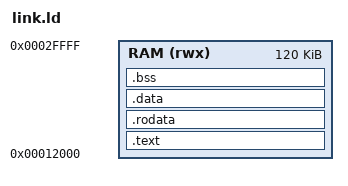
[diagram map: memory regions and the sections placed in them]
MEMORY {
	RAM (rwx): ORIGIN = 0x10000+0x2000, LENGTH = 128k-0x2000
}

ENTRY(_start);

SECTIONS {
	.text : {
		*(.text.startup)
		*(.text)
		*(.text.*)
	} >RAM

	.rodata : {
		*(.rodata)
		*(.rodata.*)
	} >RAM

	.data : {
		*(.data)
		*(.data.*)
	} >RAM

	.bss : {
		_sbss = .;
		*(.bss)
		*(.bss.*)
		*(COMMON)
		_ebss = .;
	} >RAM

	end = .;
};
